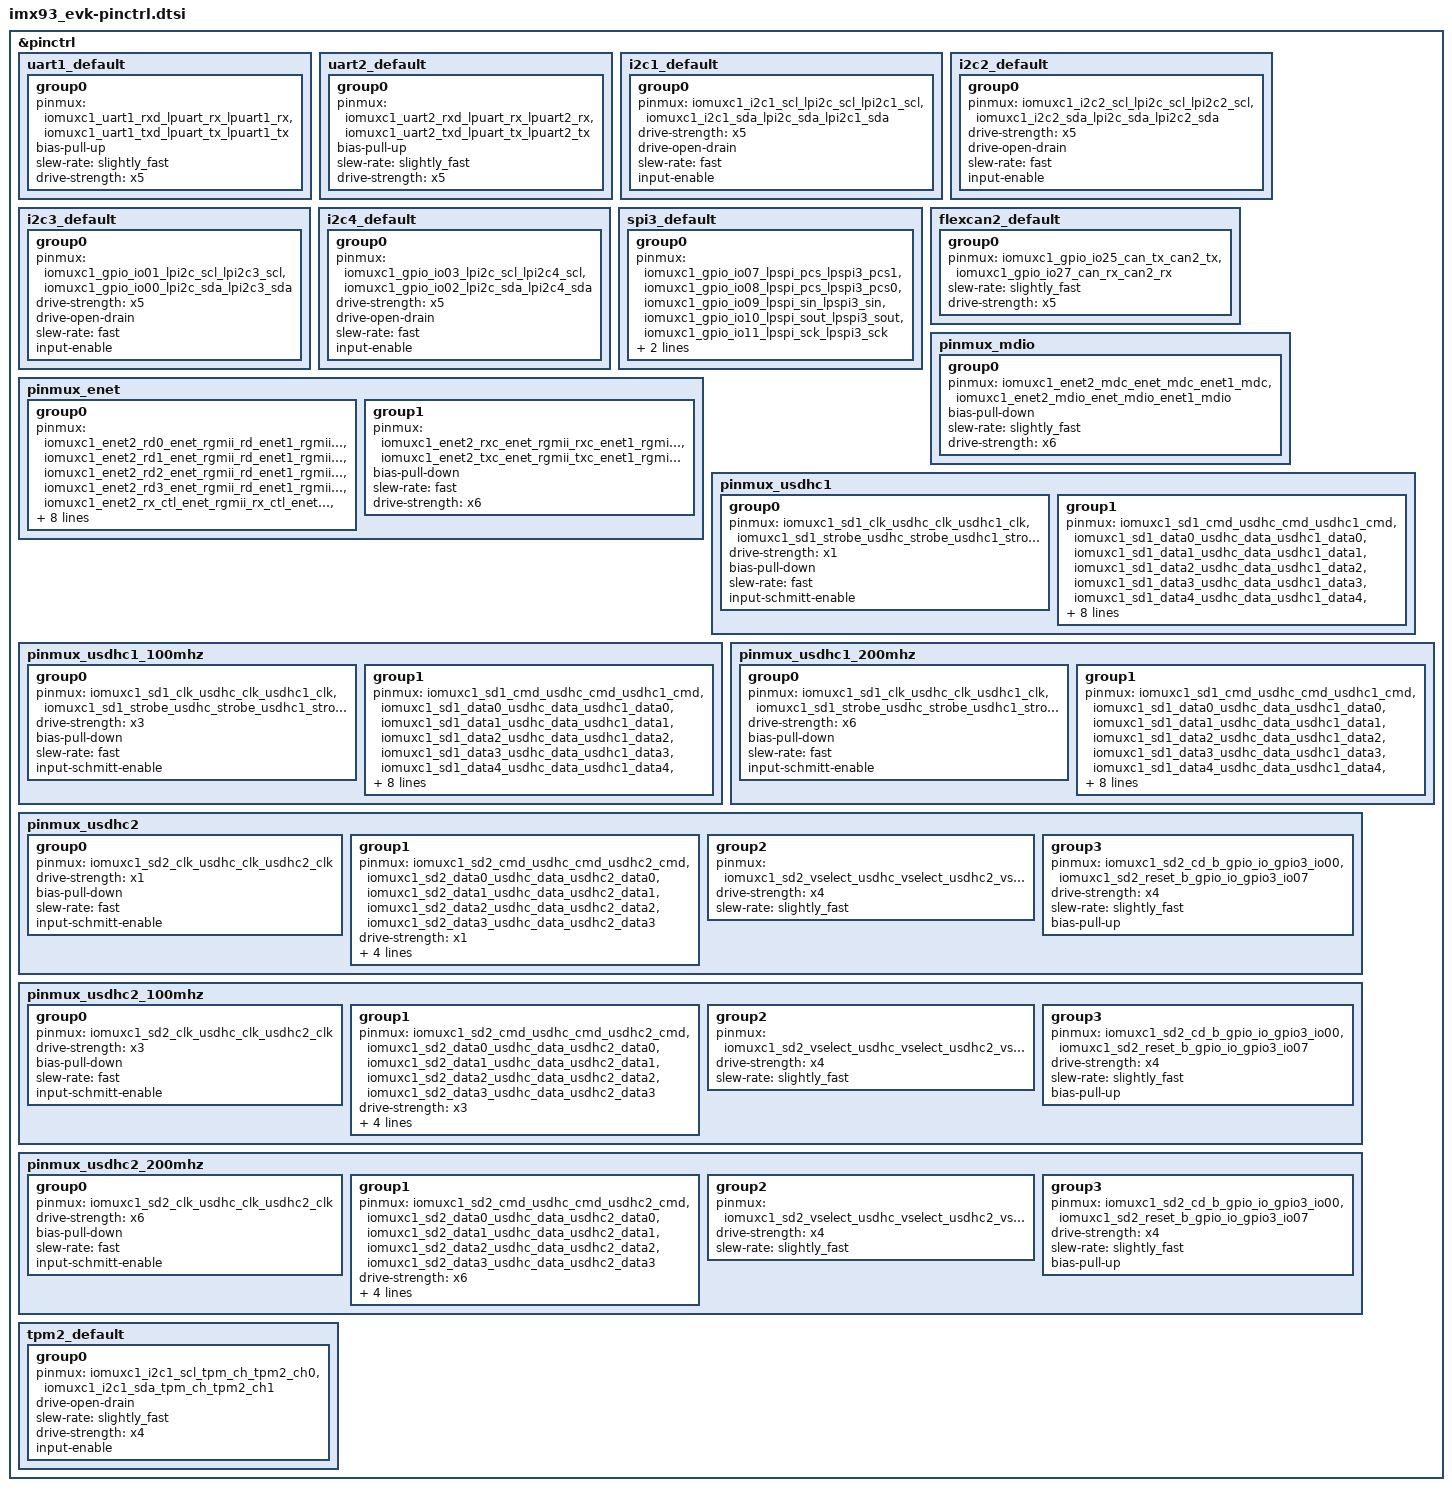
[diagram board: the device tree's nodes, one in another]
/*
 * Copyright 2022,2024 NXP
 * SPDX-License-Identifier: Apache-2.0
 *
 */

#include <nxp/nxp_imx/mimx9352cvuxk-pinctrl.dtsi>

&pinctrl {
	uart1_default: uart1_default {
		group0 {
			pinmux = <&iomuxc1_uart1_rxd_lpuart_rx_lpuart1_rx>,
				<&iomuxc1_uart1_txd_lpuart_tx_lpuart1_tx>;
			bias-pull-up;
			slew-rate = "slightly_fast";
			drive-strength = "x5";
		};
	};

	uart2_default: uart2_default {
		group0 {
			pinmux = <&iomuxc1_uart2_rxd_lpuart_rx_lpuart2_rx>,
				<&iomuxc1_uart2_txd_lpuart_tx_lpuart2_tx>;
			bias-pull-up;
			slew-rate = "slightly_fast";
			drive-strength = "x5";
		};
	};

	i2c1_default: i2c1_default {
		group0 {
			pinmux = <&iomuxc1_i2c1_scl_lpi2c_scl_lpi2c1_scl>,
				<&iomuxc1_i2c1_sda_lpi2c_sda_lpi2c1_sda>;
			drive-strength = "x5";
			drive-open-drain;
			slew-rate = "fast";
			input-enable;
		};
	};

	i2c2_default: i2c2_default {
		group0 {
			pinmux = <&iomuxc1_i2c2_scl_lpi2c_scl_lpi2c2_scl>,
				<&iomuxc1_i2c2_sda_lpi2c_sda_lpi2c2_sda>;
			drive-strength = "x5";
			drive-open-drain;
			slew-rate = "fast";
			input-enable;
		};
	};

	i2c3_default: i2c3_default {
		group0 {
			pinmux = <&iomuxc1_gpio_io01_lpi2c_scl_lpi2c3_scl>,
				<&iomuxc1_gpio_io00_lpi2c_sda_lpi2c3_sda>;
			drive-strength = "x5";
			drive-open-drain;
			slew-rate = "fast";
			input-enable;
		};
	};

	i2c4_default: i2c4_default {
		group0 {
			pinmux = <&iomuxc1_gpio_io03_lpi2c_scl_lpi2c4_scl>,
				<&iomuxc1_gpio_io02_lpi2c_sda_lpi2c4_sda>;
			drive-strength = "x5";
			drive-open-drain;
			slew-rate = "fast";
			input-enable;
		};
	};

	spi3_default: spi3_default {
		group0 {
			pinmux = <&iomuxc1_gpio_io07_lpspi_pcs_lpspi3_pcs1>,
				<&iomuxc1_gpio_io08_lpspi_pcs_lpspi3_pcs0>,
				<&iomuxc1_gpio_io09_lpspi_sin_lpspi3_sin>,
				<&iomuxc1_gpio_io10_lpspi_sout_lpspi3_sout>,
				<&iomuxc1_gpio_io11_lpspi_sck_lpspi3_sck>;
			slew-rate = "fast";
			drive-strength = "x5";
		};
	};

	flexcan2_default: flexcan2_default {
		group0 {
			pinmux = <&iomuxc1_gpio_io25_can_tx_can2_tx>,
					 <&iomuxc1_gpio_io27_can_rx_can2_rx>;
			slew-rate = "slightly_fast";
			drive-strength = "x5";
		};
	};

	pinmux_mdio: pinmux_mdio {
		group0 {
			pinmux = <&iomuxc1_enet2_mdc_enet_mdc_enet1_mdc>,
				<&iomuxc1_enet2_mdio_enet_mdio_enet1_mdio>;
			bias-pull-down;
			slew-rate = "slightly_fast";
			drive-strength = "x6";
		};
	};

	pinmux_enet: pinmux_enet {
		group0 {
			pinmux = <&iomuxc1_enet2_rd0_enet_rgmii_rd_enet1_rgmii_rd0>,
				<&iomuxc1_enet2_rd1_enet_rgmii_rd_enet1_rgmii_rd1>,
				<&iomuxc1_enet2_rd2_enet_rgmii_rd_enet1_rgmii_rd2>,
				<&iomuxc1_enet2_rd3_enet_rgmii_rd_enet1_rgmii_rd3>,
				<&iomuxc1_enet2_rx_ctl_enet_rgmii_rx_ctl_enet1_rgmii_rx_ctl>,
				<&iomuxc1_enet2_td0_enet_rgmii_td_enet1_rgmii_td0>,
				<&iomuxc1_enet2_td1_enet_rgmii_td_enet1_rgmii_td1>,
				<&iomuxc1_enet2_td2_enet_rgmii_td_enet1_rgmii_td2>,
				<&iomuxc1_enet2_td3_enet_rgmii_td_enet1_rgmii_td3>,
				<&iomuxc1_enet2_tx_ctl_enet_rgmii_tx_ctl_enet1_rgmii_tx_ctl>;
			bias-pull-down;
			slew-rate = "slightly_fast";
			drive-strength = "x6";
		};

		group1 {
			pinmux = <&iomuxc1_enet2_rxc_enet_rgmii_rxc_enet1_rgmii_rxc>,
				<&iomuxc1_enet2_txc_enet_rgmii_txc_enet1_rgmii_txc>;
			bias-pull-down;
			slew-rate = "fast";
			drive-strength = "x6";
		};

	};

	pinmux_usdhc1: pinmux_usdhc1 {
		group0 {
			pinmux = <&iomuxc1_sd1_clk_usdhc_clk_usdhc1_clk>,
				<&iomuxc1_sd1_strobe_usdhc_strobe_usdhc1_strobe>;
			drive-strength = "x1";
			bias-pull-down;
			slew-rate = "fast";
			input-schmitt-enable;
		};

		group1 {
			pinmux = <&iomuxc1_sd1_cmd_usdhc_cmd_usdhc1_cmd>,
				<&iomuxc1_sd1_data0_usdhc_data_usdhc1_data0>,
				<&iomuxc1_sd1_data1_usdhc_data_usdhc1_data1>,
				<&iomuxc1_sd1_data2_usdhc_data_usdhc1_data2>,
				<&iomuxc1_sd1_data3_usdhc_data_usdhc1_data3>,
				<&iomuxc1_sd1_data4_usdhc_data_usdhc1_data4>,
				<&iomuxc1_sd1_data5_usdhc_data_usdhc1_data5>,
				<&iomuxc1_sd1_data6_usdhc_data_usdhc1_data6>,
				<&iomuxc1_sd1_data7_usdhc_data_usdhc1_data7>;
			drive-strength = "x1";
			slew-rate = "fast";
			input-schmitt-enable;
			bias-pull-up;
			input-enable;
		};
	};

	pinmux_usdhc1_100mhz: pinmux_usdhc1_100mhz {
		group0 {
			pinmux = <&iomuxc1_sd1_clk_usdhc_clk_usdhc1_clk>,
				<&iomuxc1_sd1_strobe_usdhc_strobe_usdhc1_strobe>;
			drive-strength = "x3";
			bias-pull-down;
			slew-rate = "fast";
			input-schmitt-enable;
		};

		group1 {
			pinmux = <&iomuxc1_sd1_cmd_usdhc_cmd_usdhc1_cmd>,
				<&iomuxc1_sd1_data0_usdhc_data_usdhc1_data0>,
				<&iomuxc1_sd1_data1_usdhc_data_usdhc1_data1>,
				<&iomuxc1_sd1_data2_usdhc_data_usdhc1_data2>,
				<&iomuxc1_sd1_data3_usdhc_data_usdhc1_data3>,
				<&iomuxc1_sd1_data4_usdhc_data_usdhc1_data4>,
				<&iomuxc1_sd1_data5_usdhc_data_usdhc1_data5>,
				<&iomuxc1_sd1_data6_usdhc_data_usdhc1_data6>,
				<&iomuxc1_sd1_data7_usdhc_data_usdhc1_data7>;
			drive-strength = "x3";
			slew-rate = "fast";
			input-schmitt-enable;
			bias-pull-up;
			input-enable;
		};
	};

	pinmux_usdhc1_200mhz: pinmux_usdhc1_200mhz {
		group0 {
			pinmux = <&iomuxc1_sd1_clk_usdhc_clk_usdhc1_clk>,
				<&iomuxc1_sd1_strobe_usdhc_strobe_usdhc1_strobe>;
			drive-strength = "x6";
			bias-pull-down;
			slew-rate = "fast";
			input-schmitt-enable;
		};

		group1 {
			pinmux = <&iomuxc1_sd1_cmd_usdhc_cmd_usdhc1_cmd>,
				<&iomuxc1_sd1_data0_usdhc_data_usdhc1_data0>,
				<&iomuxc1_sd1_data1_usdhc_data_usdhc1_data1>,
				<&iomuxc1_sd1_data2_usdhc_data_usdhc1_data2>,
				<&iomuxc1_sd1_data3_usdhc_data_usdhc1_data3>,
				<&iomuxc1_sd1_data4_usdhc_data_usdhc1_data4>,
				<&iomuxc1_sd1_data5_usdhc_data_usdhc1_data5>,
				<&iomuxc1_sd1_data6_usdhc_data_usdhc1_data6>,
				<&iomuxc1_sd1_data7_usdhc_data_usdhc1_data7>;
			drive-strength = "x6";
			slew-rate = "fast";
			input-schmitt-enable;
			bias-pull-up;
			input-enable;
		};
	};

	pinmux_usdhc2: pinmux_usdhc2 {
		group0 {
			pinmux = <&iomuxc1_sd2_clk_usdhc_clk_usdhc2_clk>;
			drive-strength = "x1";
			bias-pull-down;
			slew-rate = "fast";
			input-schmitt-enable;
		};

		group1 {
			pinmux = <&iomuxc1_sd2_cmd_usdhc_cmd_usdhc2_cmd>,
				<&iomuxc1_sd2_data0_usdhc_data_usdhc2_data0>,
				<&iomuxc1_sd2_data1_usdhc_data_usdhc2_data1>,
				<&iomuxc1_sd2_data2_usdhc_data_usdhc2_data2>,
				<&iomuxc1_sd2_data3_usdhc_data_usdhc2_data3>;
			drive-strength = "x1";
			slew-rate = "fast";
			input-schmitt-enable;
			bias-pull-up;
			input-enable;
		};

		group2 {
			pinmux = <&iomuxc1_sd2_vselect_usdhc_vselect_usdhc2_vselect>;
			drive-strength = "x4";
			slew-rate = "slightly_fast";
		};

		group3 {
			pinmux = <&iomuxc1_sd2_cd_b_gpio_io_gpio3_io00>,
				<&iomuxc1_sd2_reset_b_gpio_io_gpio3_io07>;
			drive-strength = "x4";
			slew-rate = "slightly_fast";
			bias-pull-up;
		};
	};

	pinmux_usdhc2_100mhz: pinmux_usdhc2_100mhz {
		group0 {
			pinmux = <&iomuxc1_sd2_clk_usdhc_clk_usdhc2_clk>;
			drive-strength = "x3";
			bias-pull-down;
			slew-rate = "fast";
			input-schmitt-enable;
		};

		group1 {
			pinmux = <&iomuxc1_sd2_cmd_usdhc_cmd_usdhc2_cmd>,
				<&iomuxc1_sd2_data0_usdhc_data_usdhc2_data0>,
				<&iomuxc1_sd2_data1_usdhc_data_usdhc2_data1>,
				<&iomuxc1_sd2_data2_usdhc_data_usdhc2_data2>,
				<&iomuxc1_sd2_data3_usdhc_data_usdhc2_data3>;
			drive-strength = "x3";
			slew-rate = "fast";
			input-schmitt-enable;
			bias-pull-up;
			input-enable;
		};

		group2 {
			pinmux = <&iomuxc1_sd2_vselect_usdhc_vselect_usdhc2_vselect>;
			drive-strength = "x4";
			slew-rate = "slightly_fast";
		};

		group3 {
			pinmux = <&iomuxc1_sd2_cd_b_gpio_io_gpio3_io00>,
				<&iomuxc1_sd2_reset_b_gpio_io_gpio3_io07>;
			drive-strength = "x4";
			slew-rate = "slightly_fast";
			bias-pull-up;
		};
	};

	pinmux_usdhc2_200mhz: pinmux_usdhc2_200mhz {
		group0 {
			pinmux = <&iomuxc1_sd2_clk_usdhc_clk_usdhc2_clk>;
			drive-strength = "x6";
			bias-pull-down;
			slew-rate = "fast";
			input-schmitt-enable;
		};

		group1 {
			pinmux = <&iomuxc1_sd2_cmd_usdhc_cmd_usdhc2_cmd>,
				<&iomuxc1_sd2_data0_usdhc_data_usdhc2_data0>,
				<&iomuxc1_sd2_data1_usdhc_data_usdhc2_data1>,
				<&iomuxc1_sd2_data2_usdhc_data_usdhc2_data2>,
				<&iomuxc1_sd2_data3_usdhc_data_usdhc2_data3>;
			drive-strength = "x6";
			slew-rate = "fast";
			input-schmitt-enable;
			bias-pull-up;
			input-enable;
		};

		group2 {
			pinmux = <&iomuxc1_sd2_vselect_usdhc_vselect_usdhc2_vselect>;
			drive-strength = "x4";
			slew-rate = "slightly_fast";
		};

		group3 {
			pinmux = <&iomuxc1_sd2_cd_b_gpio_io_gpio3_io00>,
				<&iomuxc1_sd2_reset_b_gpio_io_gpio3_io07>;
			drive-strength = "x4";
			slew-rate = "slightly_fast";
			bias-pull-up;
		};
	};

	tpm2_default: tpm2_default {
		group0 {
			pinmux = <&iomuxc1_i2c1_scl_tpm_ch_tpm2_ch0>,
				<&iomuxc1_i2c1_sda_tpm_ch_tpm2_ch1>;
			drive-open-drain;
			slew-rate = "slightly_fast";
			drive-strength = "x4";
			input-enable;
		};
	};
};
